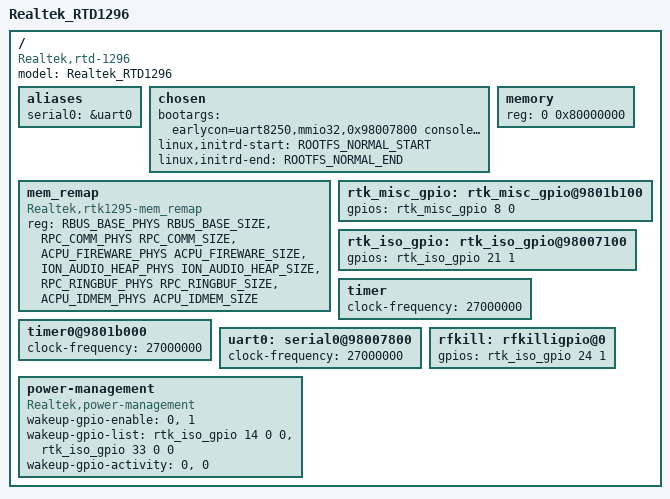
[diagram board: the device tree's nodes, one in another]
/dts-v1/;
#include "../../../../../include/soc/realtek/memory.h"

/memreserve/ SYS_BOOTCODE_MEMBASE       SYS_BOOTCODE_MEMSIZE        ; /* 0x00000000 ~ 0x00030000 */
/memreserve/ RPC_COMM_PHYS              RPC_COMM_SIZE               ; /* 0x0001f000 ~ 0x0001ffff */
/memreserve/ RESERVED_832KB_PHYS        RESERVED_832KB_SIZE         ; /* 0x00030000 ~ 0x000fffff */
/memreserve/ ACPU_FIREWARE_PHYS         ACPU_FIREWARE_SIZE          ; /* 0x01b00000 ~ 0x01efffff */
/memreserve/ RPC_RINGBUF_PHYS           RPC_RINGBUF_SIZE            ; /* 0x01ffe000 ~ 0x02001fff */
/memreserve/ ACPU_IDMEM_PHYS            ACPU_IDMEM_SIZE             ; /* 0x10000000 ~ 0x10013fff */
/memreserve/ ROOTFS_NORMAL_START        ROOTFS_NORMAL_SIZE          ; /* RootFS */

#include "rtd-1296.dtsi"
#include "rtd-129x-dvfs.dtsi"
#include "rtd-1296-saola-common.dtsi"

/ {
	model= "Realtek_RTD1296";
	compatible = "Realtek,rtd-1296";

	aliases {
		serial0 = &uart0;
	};

	chosen {
		bootargs = "earlycon=uart8250,mmio32,0x98007800 console=ttyS0,115200 androidboot.hardware=kylin loglevel=8";
		linux,initrd-start = <ROOTFS_NORMAL_START>;
		linux,initrd-end = <ROOTFS_NORMAL_END>;
	};

	memory {
		device_type = "memory";
		reg = <0 0x80000000>;	/* 2048 MB */
	};

	mem_remap {
		compatible = "Realtek,rtk1295-mem_remap";
		reg =   <RBUS_BASE_PHYS RBUS_BASE_SIZE>,
			<RPC_COMM_PHYS RPC_COMM_SIZE>,
			<ACPU_FIREWARE_PHYS ACPU_FIREWARE_SIZE>,
			<ION_AUDIO_HEAP_PHYS ION_AUDIO_HEAP_SIZE>,
			<RPC_RINGBUF_PHYS RPC_RINGBUF_SIZE>,
			<ACPU_IDMEM_PHYS ACPU_IDMEM_SIZE>;
	};

	rtk_misc_gpio: rtk_misc_gpio@9801b100 {
		gpios = <&rtk_misc_gpio 8 0 0>;
		/* install button, input, default N/A */
	};

	rtk_iso_gpio: rtk_iso_gpio@98007100 {
		gpios = <&rtk_iso_gpio 21 1 0>;
		/* igpio21, output, default low */
	};

	timer {
		clock-frequency = <27000000>;
	};

	timer0@9801b000 {
		clock-frequency = <27000000>;
	};

	uart0: serial0@98007800 {
		clock-frequency = <27000000>;
	};


	rfkill: rfkilligpio@0{
		gpios = <&rtk_iso_gpio 24 1 0>;                         /*bt power , output, default low */
		status = "okay";
	};

	power-management{
		compatible = "Realtek,power-management";

	/* GPIO Wakeup */
	wakeup-gpio-enable = /* (0) disable (1) enable */
		<0>, /* Wakeup from BT : disable */
		<1>; /* Wakeup from WiFi : disable */
	wakeup-gpio-list = /* <&rtk_iso_gpio {num} {force input (0) } {default N/A (0)] }> */
		<&rtk_iso_gpio 14 0 0>, /* BT wakeup host pin */
		<&rtk_iso_gpio 33 0 0>; /* WiFi wakeup host pin */
	wakeup-gpio-activity = /* (0) active low (1) active high*/
		<0>, /* BT : high activity */
		<0>; /* Wifi : high activity */
	};
};
